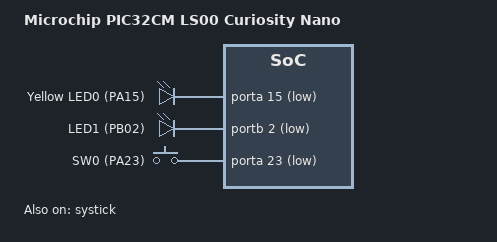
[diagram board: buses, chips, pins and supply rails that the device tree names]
/*
 * Copyright (c) 2026 Microchip Technology Inc.
 *
 * SPDX-License-Identifier: Apache-2.0
 */

/dts-v1/;

#include <microchip/pic32c/pic32cm_ls/pic32cm_ls00/pic32cm5164ls00048.dtsi>
#include <zephyr/dt-bindings/gpio/gpio.h>

/ {
	model = "Microchip PIC32CM LS00 Curiosity Nano";
	compatible = "microchip,pic32cm-ls00-cnano", "microchip,pic32cm5164ls00048";

	chosen {
		zephyr,sram = &sram0;
		zephyr,flash = &flash0;
		zephyr,systick = &systick;
	};

	aliases {
		led0 = &led0;
		led1 = &led1;
		sw0 = &button0;
	};

	leds {
		compatible = "gpio-leds";

		led0: led_0 {
			gpios = <&porta 15 GPIO_ACTIVE_LOW>;
			label = "Yellow LED0 (PA15)";
		};

		led1: led_1 {
			gpios = <&portb 2 GPIO_ACTIVE_LOW>;
			label = "LED1 (PB02)";
		};
	};

	buttons {
		compatible = "gpio-keys";

		button0: button_0 {
			gpios = <&porta 23 (GPIO_PULL_UP | GPIO_ACTIVE_LOW)>;
			label = "SW0 (PA23)";
		};
	};
};

&cpu0 {
	clock-frequency = <4000000>;
};

&systick {
	status = "okay";
};

&porta {
	status = "okay";
};

&portb {
	status = "okay";
};
